# AST1080 register map
File version: 1.0
CPU: CM4 r0p1, little endian, MPU, FPU, 4 interrupt priority bits, 256 interrupts
Registers are 32-bit, read-write, reset 0x0 unless marked. A register's access mark holds for its fields unless they carry their own. Offsets are from the block's base; [hi:lo] are bit positions; 'fields as' and 'values as' point back to an identical list.

## adc
Base 0x74C00000
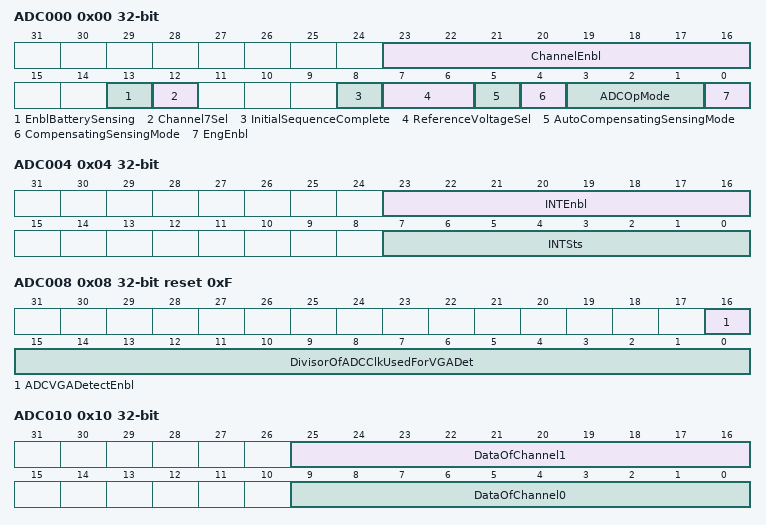
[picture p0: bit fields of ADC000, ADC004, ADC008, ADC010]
0x00 ADC000 — Engine Control
  [23:16] ChannelEnbl — Channel enable.
  [13] EnblBatterySensing — Enable Battery Sensing
  [12] Channel7Sel — Channel 7 Selection
    0=Normal_Voltage; 1=Battery
  [8] InitialSequenceComplete ro
  [7:6] ReferenceVoltageSel — Reference Voltage Selection
    0=25v; 1=12v; 2=External_Voltage_155v_To_27v; 3=External_Voltage_09v__To_165v
  [5] AutoCompensatingSensingMode
    1=Trigger_Compensating_Method; 0=Compensating_Method_Is_Done
  [4] CompensatingSensingMode
  [3:1] ADCOpMode — ADC Operation mode.
    0=Power_Down_Mode; 1=Standby_Mode; 7=Normal_Mode
  [0] EngEnbl — Engine enable.
0x04 ADC004 — Interrupt Enable and Interrupt Status
  [23:16] INTEnbl — Interrupt enable
  [7:0] INTSts — Interrupt status
0x08 ADC008 reset 0xF — ADC VGA Detect Control
  [16] ADCVGADetectEnbl — ADC VGA detect enable
  [15:0] DivisorOfADCClkUsedForVGADet — Divisor of ADC clock used for VGA detection
0x0C ADC00C reset 0xF — ADC Clock Control
  [15:0] DivisorOfADCClk — Divisor of ADC clock
0x10 ADC010 — Data of Channel 1 and 0
  [25:16] DataOfChannel1 ro, [9:0] DataOfChannel0 ro
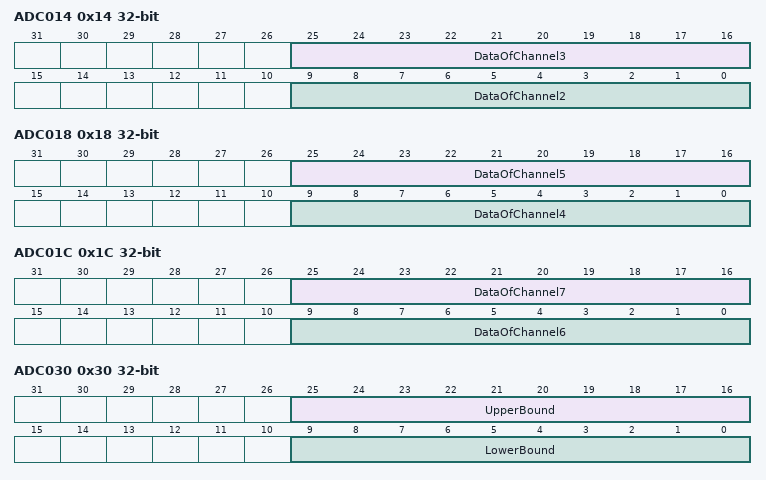
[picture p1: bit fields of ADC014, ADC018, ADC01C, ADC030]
0x14 ADC014 — Data of Channel 3 and 2
  [25:16] DataOfChannel3 ro, [9:0] DataOfChannel2 ro
0x18 ADC018 — Data of Channel 5 and 4
  [25:16] DataOfChannel5 ro, [9:0] DataOfChannel4 ro
0x1C ADC01C — Data of Channel 7 and 6
  [25:16] DataOfChannel7 ro, [9:0] DataOfChannel6 ro
0x30 ADC030 — Upper and Lower bound of Channel 0
  [25:16] UpperBound, [9:0] LowerBound
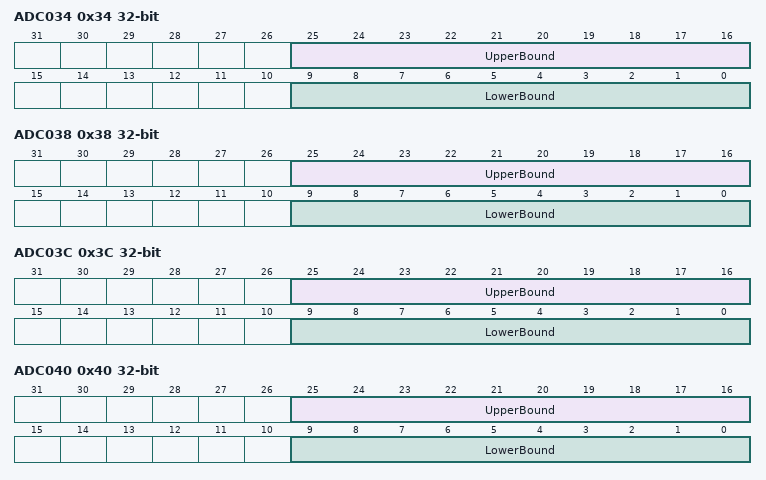
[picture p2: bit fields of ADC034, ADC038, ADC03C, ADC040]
0x34 ADC034 — Upper and Lower bound of Channel 1
  [25:16] UpperBound, [9:0] LowerBound
0x38 ADC038 — Upper and Lower bound of Channel 2
  [25:16] UpperBound, [9:0] LowerBound
0x3C ADC03C — Upper and Lower bound of Channel 3
  [25:16] UpperBound, [9:0] LowerBound
0x40 ADC040 — Upper and Lower bound of Channel 4
  [25:16] UpperBound, [9:0] LowerBound
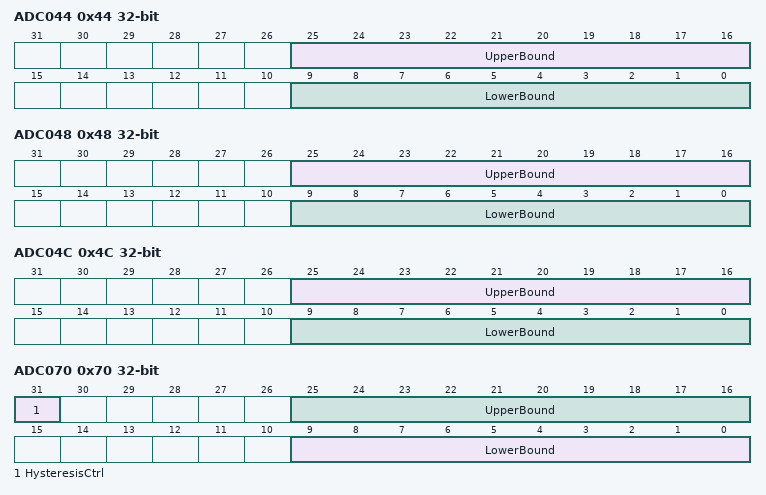
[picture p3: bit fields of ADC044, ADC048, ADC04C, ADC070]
0x44 ADC044 — Upper and Lower bound of Channel 5
  [25:16] UpperBound, [9:0] LowerBound
0x48 ADC048 — Upper and Lower bound of Channel 6
  [25:16] UpperBound, [9:0] LowerBound
0x4C ADC04C — Upper and Lower bound of Channel 7
  [25:16] UpperBound, [9:0] LowerBound
0x70 ADC070 — Hysteresis Control and bound of Channel 0
  [31] HysteresisCtrl — Hysteresis Control
    1=Enable_Hysteresis; 0=Disable_Hysteresis
  [25:16] UpperBound
  [9:0] LowerBound
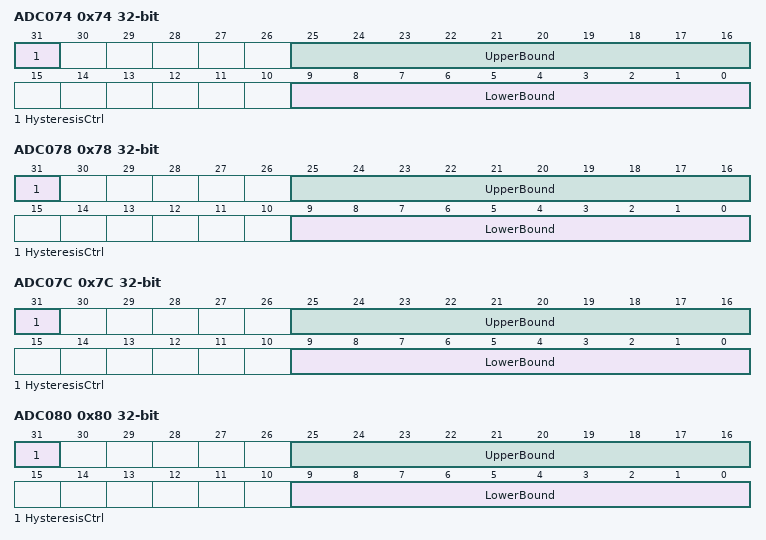
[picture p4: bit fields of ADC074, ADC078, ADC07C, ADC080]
0x74 ADC074 — Hysteresis Control and bound of Channel 1
  fields as ADC070
0x78 ADC078 — Hysteresis Control and bound of Channel 2
  fields as ADC070
0x7C ADC07C — Hysteresis Control and bound of Channel 3
  fields as ADC070
0x80 ADC080 — Hysteresis Control and bound of Channel 4
  fields as ADC070
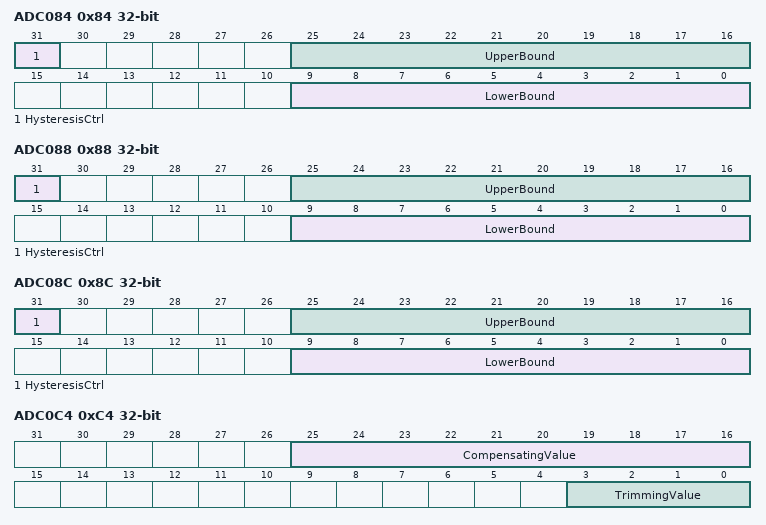
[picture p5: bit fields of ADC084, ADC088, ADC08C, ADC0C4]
0x84 ADC084 — Hysteresis Control and bound of Channel 5
  fields as ADC070
0x88 ADC088 — Hysteresis Control and bound of Channel 6
  fields as ADC070
0x8C ADC08C — Hysteresis Control and bound of Channel 7
  fields as ADC070
0xC0 ADC0C0 — Interrupt Source
  [7:0] INTSource — Interrupt Source.
0xC4 ADC0C4 — Compensating and Trimming
  [25:16] CompensatingValue ro, [3:0] TrimmingValue
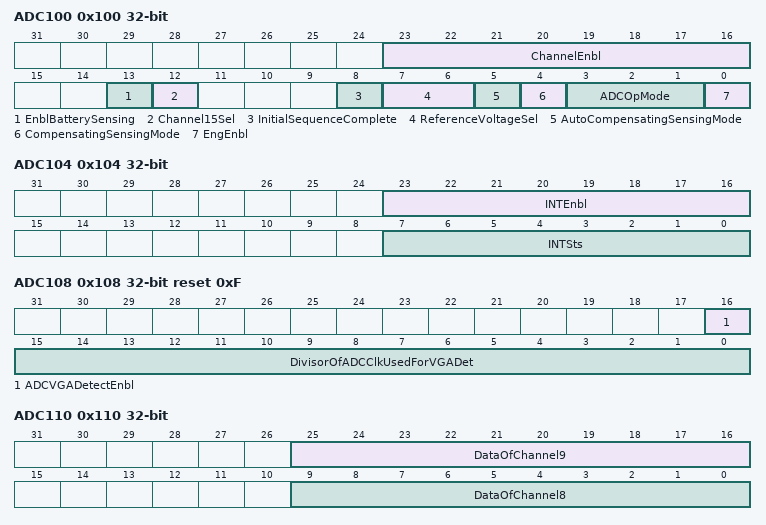
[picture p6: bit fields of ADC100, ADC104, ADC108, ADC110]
0x100 ADC100 — Engine Control
  [23:16] ChannelEnbl — Channel enable.
  [13] EnblBatterySensing — Enable Battery Sensing
  [12] Channel15Sel — Channel 15 Selection
    0=Normal_Voltage; 1=Battery
  [8] InitialSequenceComplete ro
  [7:6] ReferenceVoltageSel — Reference Voltage Selection
    values as ADC000.ReferenceVoltageSel
  [5] AutoCompensatingSensingMode
    1=Trigger_Compensating_Method; 0=Compensating_Method_Is_Done
  [4] CompensatingSensingMode
  [3:1] ADCOpMode — ADC Operation mode.
    0=Power_Down_Mode; 1=Standby_Mode; 7=Normal_Mode
  [0] EngEnbl — Engine enable.
0x104 ADC104 — Interrupt Enable and Interrupt Status
  [23:16] INTEnbl — Interrupt enable
  [7:0] INTSts — Interrupt status
0x108 ADC108 reset 0xF — ADC VGA Detect Control
  fields as ADC008
0x10C ADC10C reset 0xF — ADC Clock Control
  [15:0] DivisorOfADCClk — Divisor of ADC clock
0x110 ADC110 — Data of Channel 9 and 8
  [25:16] DataOfChannel9 ro, [9:0] DataOfChannel8 ro
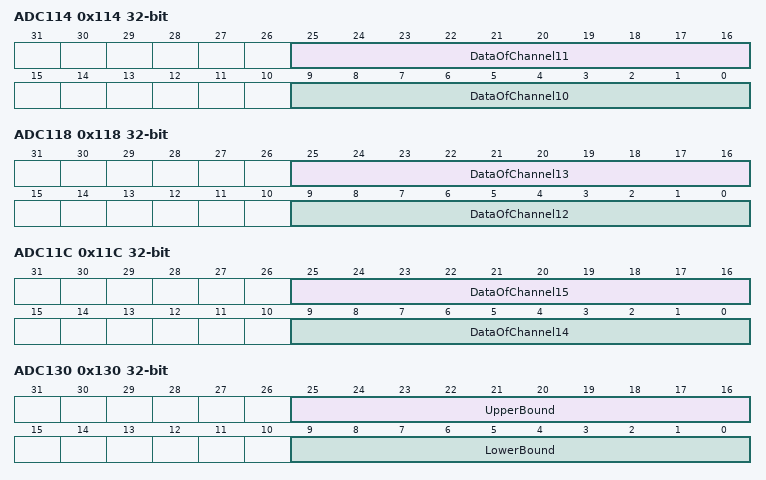
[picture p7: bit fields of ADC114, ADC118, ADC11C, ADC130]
0x114 ADC114 — Data of Channel 11 and 10
  [25:16] DataOfChannel11 ro, [9:0] DataOfChannel10 ro
0x118 ADC118 — Data of Channel 13 and 12
  [25:16] DataOfChannel13 ro, [9:0] DataOfChannel12 ro
0x11C ADC11C — Data of Channel 15 and 14
  [25:16] DataOfChannel15 ro, [9:0] DataOfChannel14 ro
0x130 ADC130 — Upper and Lower bound of Channel 8
  [25:16] UpperBound, [9:0] LowerBound
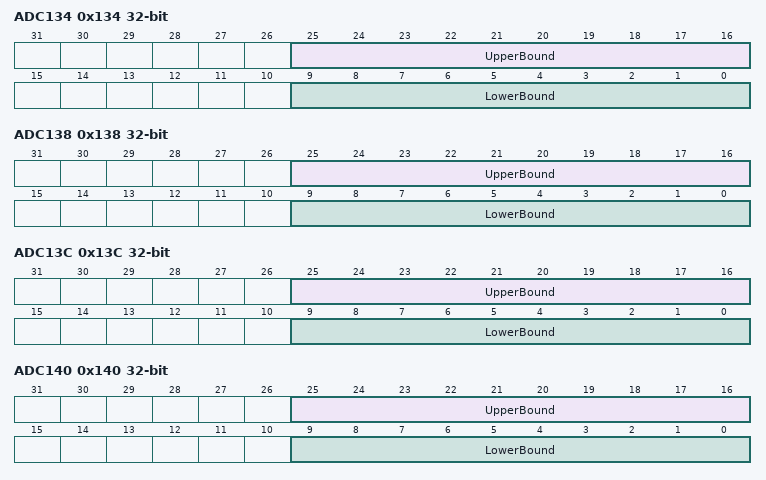
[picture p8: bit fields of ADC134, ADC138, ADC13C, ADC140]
0x134 ADC134 — Upper and Lower bound of Channel 9
  [25:16] UpperBound, [9:0] LowerBound
0x138 ADC138 — Upper and Lower bound of Channel 10
  [25:16] UpperBound, [9:0] LowerBound
0x13C ADC13C — Upper and Lower bound of Channel 11
  [25:16] UpperBound, [9:0] LowerBound
0x140 ADC140 — Upper and Lower bound of Channel 12
  [25:16] UpperBound, [9:0] LowerBound
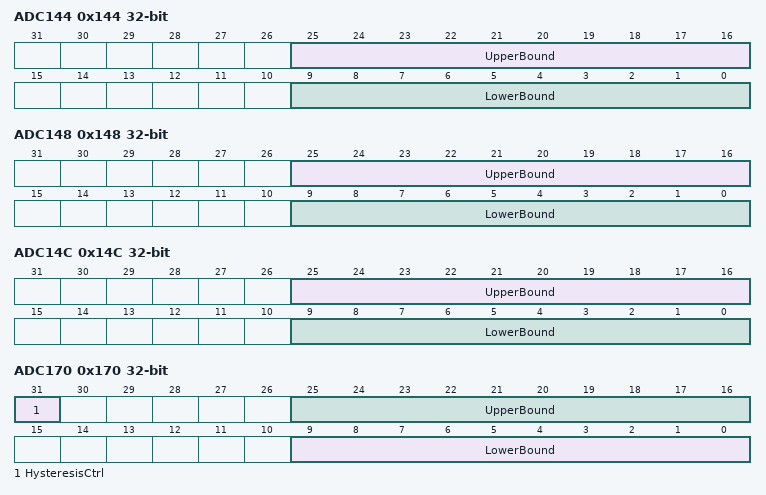
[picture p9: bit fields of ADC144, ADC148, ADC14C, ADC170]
0x144 ADC144 — Upper and Lower bound of Channel 13
  [25:16] UpperBound, [9:0] LowerBound
0x148 ADC148 — Upper and Lower bound of Channel 14
  [25:16] UpperBound, [9:0] LowerBound
0x14C ADC14C — Upper and Lower bound of Channel 15
  [25:16] UpperBound, [9:0] LowerBound
0x170 ADC170 — Hysteresis Control and bound of Channel 8
  fields as ADC070
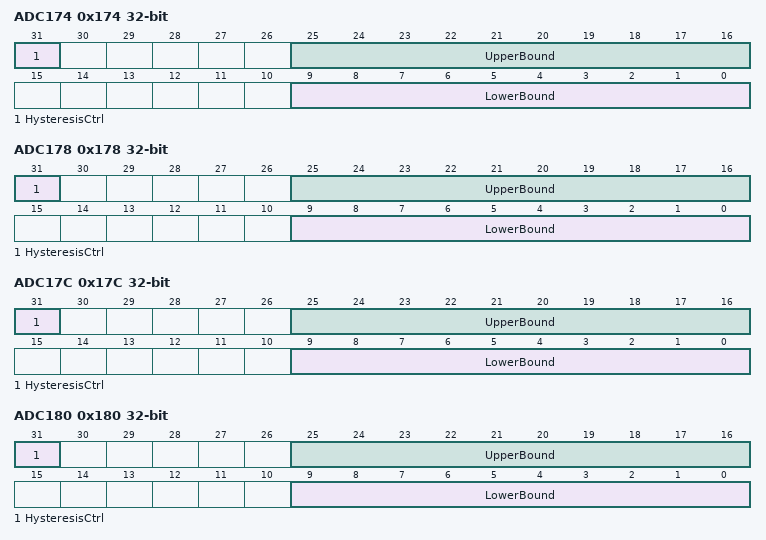
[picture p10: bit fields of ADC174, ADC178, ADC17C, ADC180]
0x174 ADC174 — Hysteresis Control and bound of Channel 9
  fields as ADC070
0x178 ADC178 — Hysteresis Control and bound of Channel 10
  fields as ADC070
0x17C ADC17C — Hysteresis Control and bound of Channel 11
  fields as ADC070
0x180 ADC180 — Hysteresis Control and bound of Channel 12
  fields as ADC070
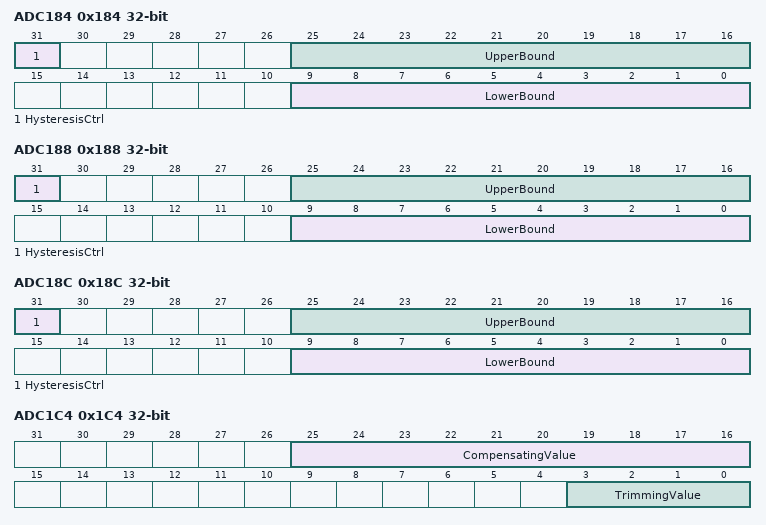
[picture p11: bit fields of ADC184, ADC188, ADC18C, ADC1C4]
0x184 ADC184 — Hysteresis Control and bound of Channel 13
  fields as ADC070
0x188 ADC188 — Hysteresis Control and bound of Channel 14
  fields as ADC070
0x18C ADC18C — Hysteresis Control and bound of Channel 15
  fields as ADC070
0x1C0 ADC1C0 — Interrupt Source
  [7:0] INTSource — Interrupt Source.
0x1C4 ADC1C4 — Compensating and Trimming
  [25:16] CompensatingValue ro, [3:0] TrimmingValue
